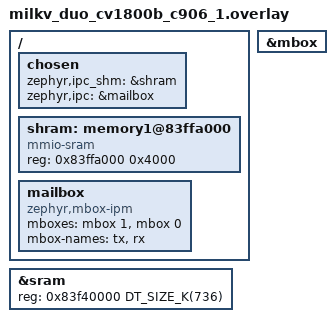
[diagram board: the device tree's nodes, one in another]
/*
 * Copyright (c) 2025, Junhui Liu <junhui.liu@pigmoral.tech>
 *
 * SPDX-License-Identifier: Apache-2.0
 */

/ {
	chosen {
		/*
		 * shared memory reserved for the inter-processor communication
		 */
		zephyr,ipc_shm = &shram;
		zephyr,ipc = &mailbox;
	};

	shram: memory1@83ffa000 {
		compatible = "mmio-sram";
		reg = <0x83ffa000 0x4000>;
	};

	mailbox: mailbox {
		compatible = "zephyr,mbox-ipm";
		mboxes = <&mbox 1>, <&mbox 0>;
		mbox-names = "tx", "rx";
	};
};

&sram {
	reg = <0x83f40000 DT_SIZE_K(736)>;
};

&mbox {
	status = "okay";
};
